VERSION "1.0"

NS_ :

BS_:

BU_: VehicleSim Cluster Tester

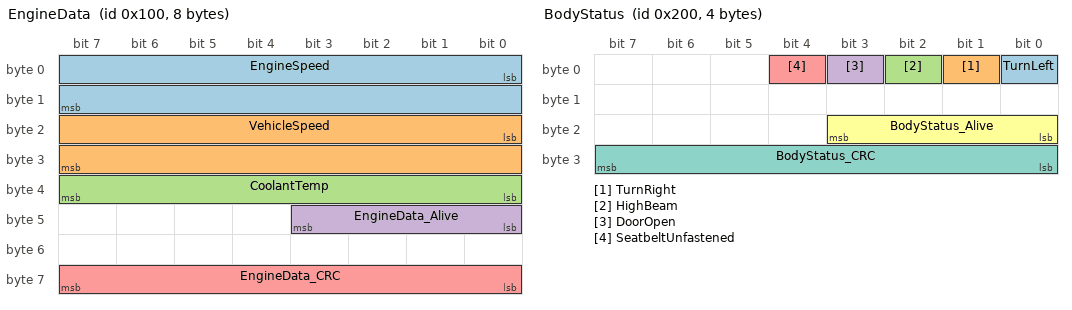
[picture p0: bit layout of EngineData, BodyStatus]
BO_ 256 EngineData: 8 VehicleSim
 SG_ EngineSpeed : 0|16@1+ (0.25,0) [0|16383.75] "rpm" Cluster
 SG_ VehicleSpeed : 16|16@1+ (0.01,0) [0|655.35] "km/h" Cluster
 SG_ CoolantTemp : 32|8@1+ (1,-40) [-40|215] "degC" Cluster
 SG_ EngineData_Alive : 40|4@1+ (1,0) [0|15] "" Cluster
 SG_ EngineData_CRC : 56|8@1+ (1,0) [0|255] "" Cluster

BO_ 512 BodyStatus: 4 VehicleSim
 SG_ TurnLeft : 0|1@1+ (1,0) [0|1] "" Cluster
 SG_ TurnRight : 1|1@1+ (1,0) [0|1] "" Cluster
 SG_ HighBeam : 2|1@1+ (1,0) [0|1] "" Cluster
 SG_ DoorOpen : 3|1@1+ (1,0) [0|1] "" Cluster
 SG_ SeatbeltUnfastened : 4|1@1+ (1,0) [0|1] "" Cluster
 SG_ BodyStatus_Alive : 16|4@1+ (1,0) [0|15] "" Cluster
 SG_ BodyStatus_CRC : 24|8@1+ (1,0) [0|255] "" Cluster

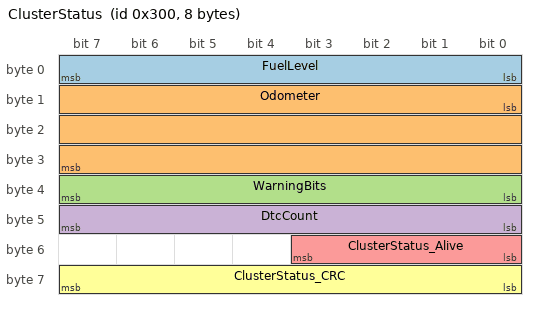
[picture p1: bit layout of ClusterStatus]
BO_ 768 ClusterStatus: 8 Cluster
 SG_ FuelLevel : 0|8@1+ (1,0) [0|100] "%" VehicleSim
 SG_ Odometer : 8|24@1+ (0.1,0) [0|1677721.5] "km" VehicleSim
 SG_ WarningBits : 32|8@1+ (1,0) [0|255] "" VehicleSim
 SG_ DtcCount : 40|8@1+ (1,0) [0|255] "" VehicleSim
 SG_ ClusterStatus_Alive : 48|4@1+ (1,0) [0|15] "" VehicleSim
 SG_ ClusterStatus_CRC : 56|8@1+ (1,0) [0|255] "" VehicleSim

BO_ 2015 DiagFunctionalReq: 8 Tester
 SG_ DiagFuncData : 0|64@1+ (1,0) [0|0] "" Cluster

BO_ 2016 DiagPhysicalReq: 8 Tester
 SG_ DiagPhysData : 0|64@1+ (1,0) [0|0] "" Cluster

BO_ 2024 DiagPhysicalResp: 8 Cluster
 SG_ DiagRespData : 0|64@1+ (1,0) [0|0] "" Tester

CM_ BO_ 256 "Engine data, cycle 20 ms, byte 6 reserved (0xFF), E2E CRC8 J1850 over DataID+bytes 0..6";
CM_ BO_ 512 "Body status, cycle 100 ms, E2E CRC8 J1850 over DataID+bytes 0..2";
CM_ BO_ 768 "Cluster status, cycle 100 ms, E2E CRC8 J1850 over DataID+bytes 0..6";
BA_DEF_ BO_ "GenMsgCycleTime" INT 0 10000;
BA_DEF_DEF_ "GenMsgCycleTime" 0;
BA_ "GenMsgCycleTime" BO_ 256 20;
BA_ "GenMsgCycleTime" BO_ 512 100;
BA_ "GenMsgCycleTime" BO_ 768 100;
